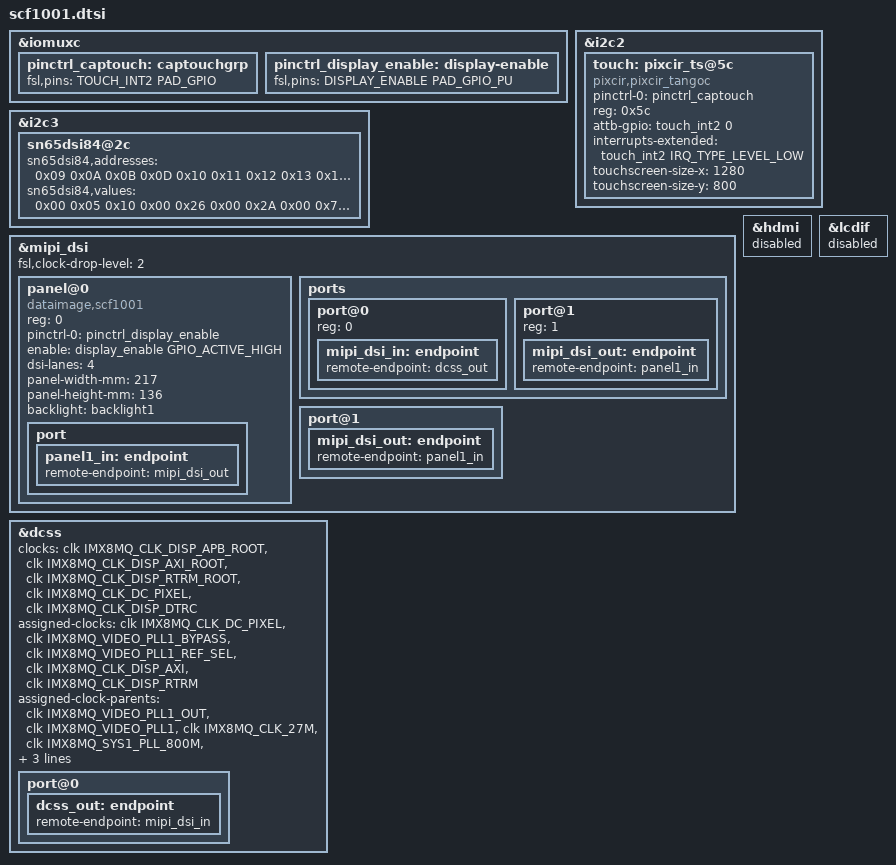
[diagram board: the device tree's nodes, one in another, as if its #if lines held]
/*
 * Copyright 2020 Keith & Koep GmbH
 *
 */

 /*
Defines:
    TOUCH_USE_INT2  Set if alternate touch-interrupt should be used.

    TOUCH_INT      Defined in xxx_pinfunc.h. (SODIMM-pin: 45: pConXS)
    TOUCH_INT2     Defined in xxx_pinfunc.h. (SODIMM-pin: 55: i-PANT7, i-PAN T10)

*/

&iomuxc {
	pinctrl_captouch: captouchgrp {
        fsl,pins = <
#if defined(TOUCH_USE_INT2) && (TOUCH_USE_INT2==1)
					 TOUCH_INT2 		PAD_GPIO /* IRQ */
#else
					 TOUCH_INT  		PAD_GPIO /* IRQ */
#endif
                >;
	};
		
	pinctrl_display_enable: display-enable 	{
		fsl,pins = < DISPLAY_ENABLE		PAD_GPIO_PU >; /* DISPLAY_ENABLE */
	};
};

&i2c2 {
	touch: pixcir_ts@5c {
		compatible = "pixcir,pixcir_tangoc";
		pinctrl-names = "default";
		pinctrl-0 = <&pinctrl_captouch>;
		reg = <0x5c>;

#if defined(TOUCH_USE_INT2) && (TOUCH_USE_INT2==1)
		attb-gpio = <touch_int2 0>;
		interrupts-extended = <touch_int2 IRQ_TYPE_LEVEL_LOW>;
#else
		attb-gpio = <touch_int 0>;
		interrupts-extended = <touch_int IRQ_TYPE_LEVEL_LOW>;
#endif
		touchscreen-size-x = <1280>;
		touchscreen-size-y = <800>;
	};
};

&i2c3 {
	sn65dsi84@2c {
		status = "ok";
		sn65dsi84,addresses = <	0x09 0x0A 0x0B 0x0D 0x10 0x11 0x12 0x13
		        				0x18 0x19 0x1A 0x1B 0x20 0x21 0x22 0x23 
				        		0x24 0x25 0x26 0x27 0x28 0x29 0x2A 0x2B 
						        0x2C 0x2D 0x2E 0x2F 0x30 0x31 0x32 0x33 
		        				0x34 0x35 0x36 0x37 0x38 0x39 0x3A 0x3B 
				        		0x3C 0x3D 0x3E 0x0D>;
		sn65dsi84,values =    <	0x00 0x05 0x10 0x00 0x26 0x00 0x2A 0x00
			        			0x78 0x00 0x03 0x00 0x00 0x05 0x00 0x00 
        						0x00 0x00 0x00 0x00 0x21 0x00 0x00 0x00 
                                0x3C 0x00 0x00 0x00 0x03 0x00 0x00 0x00
		        				0x30 0x00 0x00 0x00 0x00 0x00 0x00 0x00
				        		0x00 0x00 0x00 0x01>;
	};

};

&mipi_dsi {
	status              = "okay";
	panel@0 {
		status          = "okay";
		compatible      = "dataimage,scf1001";
		reg             = <0>;
		pinctrl-0       = <&pinctrl_display_enable>;
		enable          = <display_enable GPIO_ACTIVE_HIGH>;
		dsi-lanes       = <4>;
		panel-width-mm  = <217>;
		panel-height-mm = <136>;
		backlight       = <&backlight1>;

		port {
			panel1_in: endpoint {
				remote-endpoint = <&mipi_dsi_out>;
			};
		};
	};
};

/************************************************************************/
#if defined (__DTS_TRIZEPS8_PINFUNC_H)
&hdmi {
	status = "disabled";
};

&lcdif {
	status = "disabled";
};

&dcss {
	status = "okay";

	clocks = <&clk IMX8MQ_CLK_DISP_APB_ROOT>,
		 <&clk IMX8MQ_CLK_DISP_AXI_ROOT>,
		 <&clk IMX8MQ_CLK_DISP_RTRM_ROOT>,
		 <&clk IMX8MQ_CLK_DC_PIXEL>,
		 <&clk IMX8MQ_CLK_DISP_DTRC>;
	clock-names = "apb", "axi", "rtrm", "pix", "dtrc";
	assigned-clocks = <&clk IMX8MQ_CLK_DC_PIXEL>,
					  <&clk IMX8MQ_VIDEO_PLL1_BYPASS>,
					  <&clk IMX8MQ_VIDEO_PLL1_REF_SEL>,
					  <&clk IMX8MQ_CLK_DISP_AXI>,
					  <&clk IMX8MQ_CLK_DISP_RTRM>;
	assigned-clock-parents = <&clk IMX8MQ_VIDEO_PLL1_OUT>,
							 <&clk IMX8MQ_VIDEO_PLL1>,
							 <&clk IMX8MQ_CLK_27M>,
							 <&clk IMX8MQ_SYS1_PLL_800M>,
							 <&clk IMX8MQ_SYS1_PLL_800M>;
	assigned-clock-rates = <600000000>, <0>, <0>,
						   <800000000>,
						   <400000000>;

	port@0 {
		dcss_out: endpoint {
			remote-endpoint = <&mipi_dsi_in>;
		};
	};
};

&mipi_dsi {
    fsl,clock-drop-level = <2>;
	ports {
		#address-cells = <1>;
		#size-cells = <0>;

		port@0 {
			reg = <0>;
			mipi_dsi_in: endpoint {
				remote-endpoint = <&dcss_out>;
			};
		};

		port@1 {
			reg = <1>;
			mipi_dsi_out: endpoint {
				remote-endpoint = <&panel1_in>;
			};
		};
	};
};
#endif
/************************************************************************/
#if defined (__DTS_IMX8MM_PINFUNC_H) || defined (__DTS_IMX8MN_PINFUNC_H)
&mipi_dsi {
	port@1 {
		mipi_dsi_out: endpoint {
			remote-endpoint = <&panel1_in>;
		};
	};
};
#endif
/************************************************************************/

